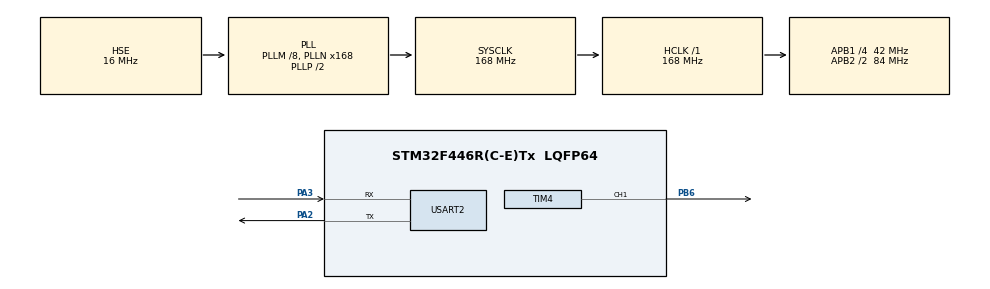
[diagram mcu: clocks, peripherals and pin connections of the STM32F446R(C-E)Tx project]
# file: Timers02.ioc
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Mcu.Family=STM32F4
Mcu.Name=STM32F446R(C-E)Tx
Mcu.Package=LQFP64
NVIC.PriorityGroup=NVIC_PRIORITYGROUP_4
PA13.Mode=Trace_Asynchronous_SW
PA13.Signal=SYS_JTMS-SWDIO
PA14.Mode=Trace_Asynchronous_SW
PA14.Signal=SYS_JTCK-SWCLK
PA2.Mode=Asynchronous
PA2.Signal=USART2_TX
PA3.Mode=Asynchronous
PA3.Signal=USART2_RX
PB3.Mode=Trace_Asynchronous_SW
PB3.Signal=SYS_JTDO-SWO
PB6.Signal=S_TIM4_CH1
PH0-OSC_IN.Mode=HSE-External-Oscillator
PH0-OSC_IN.Signal=RCC_OSC_IN
PH1-OSC_OUT.Mode=HSE-External-Oscillator
PH1-OSC_OUT.Signal=RCC_OSC_OUT
ProjectManager.HeapSize=0x200
ProjectManager.StackSize=0x400
ProjectManager.TargetToolchain=STM32CubeIDE
RCC.AHBFreq_Value=168000000
RCC.APB1CLKDivider=RCC_HCLK_DIV4
RCC.APB1Freq_Value=42000000
RCC.APB1TimFreq_Value=84000000
RCC.APB2CLKDivider=RCC_HCLK_DIV2
RCC.APB2Freq_Value=84000000
RCC.APB2TimFreq_Value=168000000
RCC.CortexFreq_Value=168000000
RCC.HCLKFreq_Value=168000000
RCC.HSE_VALUE=16000000
RCC.PLLM=8
RCC.PLLN=168
RCC.PLLSourceVirtual=RCC_PLLSOURCE_HSE
RCC.SYSCLKFreq_VALUE=168000000
RCC.SYSCLKSource=RCC_SYSCLKSOURCE_PLLCLK
RCC.USBFreq_Value=168000000
RCC.VCOOutputFreq_Value=336000000
SH.S_TIM4_CH1.0=TIM4_CH1,PWM Generation1 CH1
TIM4.Channel-PWM\ Generation1\ CH1=TIM_CHANNEL_1
TIM4.Period=1399
TIM4.Prescaler=59999
TIM4.Pulse-PWM\ Generation1\ CH1=100
USART2.VirtualMode=VM_ASYNC
VP_TIM4_VS_ClockSourceINT.Mode=Internal
board=custom

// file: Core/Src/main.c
/* USER CODE BEGIN Header */
/**
 ******************************************************************************
 * @file           : main.c
 * @brief          : Main program body
 ******************************************************************************
 * @attention
 *
 * Copyright (c) 2026 STMicroelectronics.
 * All rights reserved.
 *
 * This software is licensed under terms that can be found in the LICENSE file
 * in the root directory of this software component.
 * If no LICENSE file comes with this software, it is provided AS-IS.
 *
 ******************************************************************************
 */
/* USER CODE END Header */
#include "main.h"

/* USER CODE BEGIN Includes */
#include <stdlib.h>
#include <stdio.h>
/* USER CODE END Includes */

TIM_HandleTypeDef htim4;

UART_HandleTypeDef huart2;

void SystemClock_Config(void);
static void MX_GPIO_Init(void);
static void MX_USART2_UART_Init(void);
static void MX_TIM4_Init(void);

/* USER CODE BEGIN 0 */
// Send pringf to uart2
int _write(int file, char *ptr, int len)
{
	HAL_UART_Transmit(&huart2, (uint8_t*) ptr, len, HAL_MAX_DELAY);
	return len;
}
/* USER CODE END 0 */

int main(void)
{

	/* MCU Configuration--------------------------------------------------------*/

	/* Reset of all peripherals, Initializes the Flash interface and the Systick. */
	HAL_Init();

	/* Configure the system clock */
	SystemClock_Config();

	/* Initialize all configured peripherals */
	MX_GPIO_Init();
	MX_USART2_UART_Init();
	MX_TIM4_Init();
	/* USER CODE BEGIN 2 */

	printf("\r\n\r\n\r\nStarting Timers02...\r\n");

	// This isn't needed, it was used with interrupts in a previous project
	//HAL_TIM_Base_Start_IT(&htim4);

	// Start the timer
	HAL_TIM_PWM_Start(&htim4, TIM_CHANNEL_1);

	// Set the Pulse length
	__HAL_TIM_SET_COMPARE(&htim4, TIM_CHANNEL_1, 1200);
	/* USER CODE END 2 */

	/* Infinite loop */
	/* USER CODE BEGIN WHILE */

	uint32_t msSinceReset = 0;
	uint32_t nextTick = 0;
	uint32_t loopCount = 0;

	while (1)
	{
		msSinceReset = HAL_GetTick(); // number of milliseconds since power on or reset

		if (msSinceReset >= nextTick)
		{
			printf("Tick: %lu (Loop Count: %lu)\r\n", msSinceReset / 1000, loopCount);

			loopCount = 0;

			nextTick = msSinceReset + 1000;

		}

		loopCount++;

		/* USER CODE END WHILE */

	}
}

void SystemClock_Config(void)
{
	RCC_OscInitTypeDef RCC_OscInitStruct =
	{ 0 };
	RCC_ClkInitTypeDef RCC_ClkInitStruct =
	{ 0 };

	/** Configure the main internal regulator output voltage
	 */
	__HAL_RCC_PWR_CLK_ENABLE();
	__HAL_PWR_VOLTAGESCALING_CONFIG(PWR_REGULATOR_VOLTAGE_SCALE1);

	/** Initializes the RCC Oscillators according to the specified parameters
	 * in the RCC_OscInitTypeDef structure.
	 */
	RCC_OscInitStruct.OscillatorType = RCC_OSCILLATORTYPE_HSE;
	RCC_OscInitStruct.HSEState = RCC_HSE_ON;
	RCC_OscInitStruct.PLL.PLLState = RCC_PLL_ON;
	RCC_OscInitStruct.PLL.PLLSource = RCC_PLLSOURCE_HSE;
	RCC_OscInitStruct.PLL.PLLM = 8;
	RCC_OscInitStruct.PLL.PLLN = 168;
	RCC_OscInitStruct.PLL.PLLP = RCC_PLLP_DIV2;
	RCC_OscInitStruct.PLL.PLLQ = 2;
	RCC_OscInitStruct.PLL.PLLR = 2;
	if (HAL_RCC_OscConfig(&RCC_OscInitStruct) != HAL_OK)
	{
		Error_Handler();
	}

	/** Initializes the CPU, AHB and APB buses clocks
	 */
	RCC_ClkInitStruct.ClockType = RCC_CLOCKTYPE_HCLK | RCC_CLOCKTYPE_SYSCLK
			| RCC_CLOCKTYPE_PCLK1 | RCC_CLOCKTYPE_PCLK2;
	RCC_ClkInitStruct.SYSCLKSource = RCC_SYSCLKSOURCE_PLLCLK;
	RCC_ClkInitStruct.AHBCLKDivider = RCC_SYSCLK_DIV1;
	RCC_ClkInitStruct.APB1CLKDivider = RCC_HCLK_DIV4;
	RCC_ClkInitStruct.APB2CLKDivider = RCC_HCLK_DIV2;

	if (HAL_RCC_ClockConfig(&RCC_ClkInitStruct, FLASH_LATENCY_5) != HAL_OK)
	{
		Error_Handler();
	}
}

static void MX_TIM4_Init(void)
{

	TIM_ClockConfigTypeDef sClockSourceConfig =
	{ 0 };
	TIM_MasterConfigTypeDef sMasterConfig =
	{ 0 };
	TIM_OC_InitTypeDef sConfigOC =
	{ 0 };

	htim4.Instance = TIM4;
	htim4.Init.Prescaler = 59999;
	htim4.Init.CounterMode = TIM_COUNTERMODE_UP;
	htim4.Init.Period = 1399;
	htim4.Init.ClockDivision = TIM_CLOCKDIVISION_DIV1;
	htim4.Init.AutoReloadPreload = TIM_AUTORELOAD_PRELOAD_DISABLE;
	if (HAL_TIM_Base_Init(&htim4) != HAL_OK)
	{
		Error_Handler();
	}
	sClockSourceConfig.ClockSource = TIM_CLOCKSOURCE_INTERNAL;
	if (HAL_TIM_ConfigClockSource(&htim4, &sClockSourceConfig) != HAL_OK)
	{
		Error_Handler();
	}
	if (HAL_TIM_PWM_Init(&htim4) != HAL_OK)
	{
		Error_Handler();
	}
	sMasterConfig.MasterOutputTrigger = TIM_TRGO_RESET;
	sMasterConfig.MasterSlaveMode = TIM_MASTERSLAVEMODE_DISABLE;
	if (HAL_TIMEx_MasterConfigSynchronization(&htim4, &sMasterConfig) != HAL_OK)
	{
		Error_Handler();
	}
	sConfigOC.OCMode = TIM_OCMODE_PWM1;
	sConfigOC.Pulse = 100;
	sConfigOC.OCPolarity = TIM_OCPOLARITY_HIGH;
	sConfigOC.OCFastMode = TIM_OCFAST_DISABLE;
	if (HAL_TIM_PWM_ConfigChannel(&htim4, &sConfigOC, TIM_CHANNEL_1) != HAL_OK)
	{
		Error_Handler();
	}
	HAL_TIM_MspPostInit(&htim4);

}

static void MX_USART2_UART_Init(void)
{

	huart2.Instance = USART2;
	huart2.Init.BaudRate = 115200;
	huart2.Init.WordLength = UART_WORDLENGTH_8B;
	huart2.Init.StopBits = UART_STOPBITS_1;
	huart2.Init.Parity = UART_PARITY_NONE;
	huart2.Init.Mode = UART_MODE_TX_RX;
	huart2.Init.HwFlowCtl = UART_HWCONTROL_NONE;
	huart2.Init.OverSampling = UART_OVERSAMPLING_16;
	if (HAL_UART_Init(&huart2) != HAL_OK)
	{
		Error_Handler();
	}

}

static void MX_GPIO_Init(void)
{

	/* GPIO Ports Clock Enable */
	__HAL_RCC_GPIOH_CLK_ENABLE();
	__HAL_RCC_GPIOA_CLK_ENABLE();
	__HAL_RCC_GPIOB_CLK_ENABLE();

}

void Error_Handler(void)
{
	__disable_irq();
	while (1)
	{
	}
}
